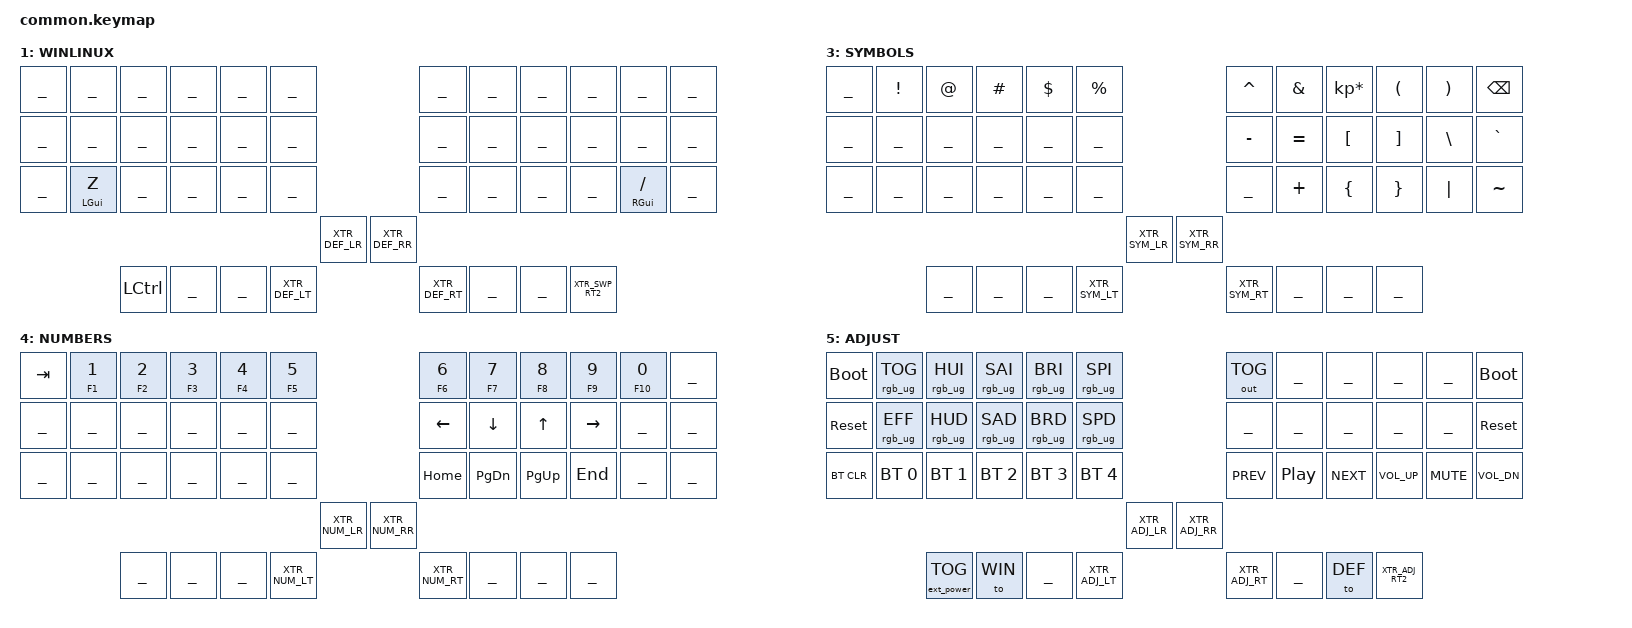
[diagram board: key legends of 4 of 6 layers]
#include <behaviors.dtsi>
#include <dt-bindings/zmk/keys.h>
#include <dt-bindings/zmk/bt.h>
#include <dt-bindings/zmk/rgb.h>
#include <dt-bindings/zmk/ext_power.h>
#include <dt-bindings/zmk/outputs.h>

#include "helpers.h"
#include "extra_keys_defaults.h"

// Left bottom row pinky 2nd column
#ifndef LB5
#define LB5 24
#endif

// Right bottom row pinky 2nd column
#ifndef RB5
#define RB5 35
#endif


#define DEF 0
#define WIN 1
#define SWP 2
#define SYM 3
#define NUM 4
#define ADJ 5


#define QUICK_TAP_MS 175

#define DEFAULT_LAYOUT \
      /* ╭─────────────┬─────────────┬─────────────┬─────────────┬─────────────┬─────────────╮                                      ╭─────────────┬─────────────┬─────────────┬─────────────┬─────────────┬────────────╮   */ \
          &ht GRAVE TAB,   &ht N1 Q,    &ht N2 W,     &ht N3 E,     &ht N4 R,     &ht N5 T,                                             &ht N6 Y,    &ht N7 U,     &ht N8 I,     &ht N9 O,     &ht N0 P,    &kp PIPE,         \
      /* ├─────────────┼─────────────┼─────────────┼─────────────┼─────────────┼─────────────┤                                      ├─────────────┼─────────────┼─────────────┼─────────────┼─────────────┼────────────┤   */ \
           &kp ESC,         &kp A,        &kp S,        &kp D,        &kp F,       &kp G,                                                &kp H,        &kp J,        &kp K,        &kp L,       &kp SEMI,    &kp SQT,         \
      /* ├─────────────┼─────────────┼─────────────┼─────────────┼─────────────┼─────────────┤  ╭─────────────╮     ╭─────────────╮ ├─────────────┼─────────────┼─────────────┼─────────────┼─────────────┼────────────┤   */ \
           &sk LSHFT,  &mt_sk LCTRL Z, &mt_sk LALT X,   &kp C,        &kp V,       &kp B,                                                &kp N,        &kp M,       &kp COMMA, &mt_sk RALT DOT, &mt_sk RCTRL FSLH, &sk RSHFT, \
                                                                                                  XTR_DEF_LR,          XTR_DEF_RR,                                                                                            \
      /* ╰─────────────┴─────────────┼─────────────┼─────────────┼─────────────┼─────────────┤  ╰─────────────╯     ╰─────────────╯ ├─────────────┼─────────────┼─────────────┼─────────────┼─────────────┴────────────╯   */ \
                                          &lswp,     &kp SPACE,  &lt_qk SYM BKSP, XTR_DEF_LT,                                          XTR_DEF_RT,  &lt_qk NUM DEL,  &kp RET,    &tog SWP  
      /*                             ╰─────────────┴─────────────┴─────────────┴─────────────╯                                      ╰─────────────┴─────────────┴─────────────┴─────────────╯                              */


&sk {
  release-after-ms = <600>;
  quick-release;
};

/ {
  conditional_layers {
    compatible = "zmk,conditional-layers";
    tri_layer {
      if-layers = <SYM NUM>;
      then-layer = <ADJ>;
    };
  };

  combos {
    compatible = "zmk,combos";
    caps {
      timeout-ms = <50>;
      key-positions = <LB5 RB5>;
      bindings = <&caps_word>;
    };
  };

  behaviors {
    lt_qk: layer_toggle_quick {
      compatible = "zmk,behavior-hold-tap";
      label = "LAYER_TOGGLE_QUICK";
      #binding-cells = <2>;
      flavor = "tap-preferred";
      tapping-term-ms = <150>;
      quick-tap-ms = <QUICK_TAP_MS>;
      bindings = <&mo>, <&kp>;
    };
    mt_sk: mod_tap_sticky {
      compatible = "zmk,behavior-hold-tap";
      label = "MOD_TAP_STICKY";
      #binding-cells = <2>;
      flavor = "tap-preferred";
      tapping-term-ms = <150>;
      quick-tap-ms = <200>;
      bindings = <&sk>, <&kp>;
    };
    ht: hold_tap {
      compatible = "zmk,behavior-hold-tap";
      label = "HOLD_TAP";
      #binding-cells = <2>;
      tapping_term_ms = <200>;
      quick_tap_ms = <200>;
      flavor = "tap-preferred";
      bindings = <&kp>, <&kp>;
    };
    lswp: lswp { \
        label = "SWAP"; \
        compatible = "zmk,behavior-tap-dance"; \
        #binding-cells = <0>; \
        tapping-term-ms = <200>; \
        bindings = <&sk LGUI>, <&tog SWP>; \
    }; \
  };

  keymap {
    compatible = "zmk,keymap";
    default_layer {
      label = "DEFAULT";
      bindings = <LAYOUT_wrapper(DEFAULT_LAYOUT)>;
    };
    
    winlinux_layer {
      label = "WINLINUX";
      bindings = <
      // ╭─────────────┬─────────────┬─────────────┬─────────────┬─────────────┬─────────────╮                                      ╭─────────────┬─────────────┬─────────────┬─────────────┬─────────────┬────────────╮
              ___          ___            ___            ___           ___          ___                                                  ___          ___            ___            ___           ___          ___       
      // ├─────────────┼─────────────┼─────────────┼─────────────┼─────────────┼─────────────┤                                      ├─────────────┼─────────────┼────────────┼─────────────┼─────────────┼────────────┤
              ___          ___            ___            ___           ___          ___                                                  ___          ___            ___            ___           ___          ___       
      // ├─────────────┼─────────────┼─────────────┼─────────────┼─────────────┼─────────────┤  ╭─────────────╮     ╭─────────────╮ ├─────────────┼─────────────┼─────────────┼─────────────┼─────────────┼────────────┤
              ___      &mt_sk LGUI Z      ___            ___           ___          ___                                                  ___           ___           ___            ___    &mt_sk RGUI FSLH    ___ 
                                                                                                  XTR_DEF_LR          XTR_DEF_RR                                                                                   
      // ╰─────────────┴─────────────┼─────────────┼─────────────┼─────────────┼─────────────┤  ╰─────────────╯     ╰─────────────╯ ├─────────────┼─────────────┼─────────────┼─────────────┼─────────────┴────────────╯
                                       &kp LCTRL         ___           ___        XTR_DEF_LT                                           XTR_DEF_RT      ___           ___        XTR_SWP_RT2        
      //                             ╰─────────────┴─────────────┴─────────────┴─────────────╯                                      ╰─────────────┴─────────────┴─────────────┴─────────────╯
      >;
    };
    swap_layer {
      label = "SWAP";
      bindings = <SWAP_LAYOUT_wrapper(DEFAULT_LAYOUT)>;
    };
    sym_layer {
      label = "SYMBOLS";
      bindings = <
      // ╭─────────────┬─────────────┬─────────────┬─────────────┬─────────────┬─────────────╮                                      ╭─────────────┬─────────────┬─────────────┬─────────────┬─────────────┬────────────╮
              ___          &kp EXCL      &kp AT        &kp HASH      &kp DLLR    &kp PRCNT                                             &kp CARET      &kp AMPS   &kp KP_MULTIPLY &kp LPAR       &kp RPAR     &kp BSPC
      // ├─────────────┼─────────────┼─────────────┼─────────────┼─────────────┼─────────────┤                                      ├─────────────┼─────────────┼─────────────┼─────────────┼─────────────┼────────────┤
              ___          ___            ___            ___           ___          ___                                                &kp MINUS      &kp EQUAL     &kp LBKT     &kp RBKT       &kp BSLH     &kp GRAVE
      // ├─────────────┼─────────────┼─────────────┼─────────────┼─────────────┼─────────────┤  ╭─────────────╮     ╭─────────────╮ ├─────────────┼─────────────┼─────────────┼─────────────┼─────────────┼────────────┤
              ___          ___            ___            ___           ___          ___                                                &kp UNDER      &kp PLUS      &kp LBRC     &kp RBRC       &kp PIPE     &kp TILDE
                                                                                                  XTR_SYM_LR          XTR_SYM_RR                                                                                      
      // ╰─────────────┴─────────────┼─────────────┼─────────────┼─────────────┼─────────────┤  ╰─────────────╯     ╰─────────────╯ ├─────────────┼─────────────┼─────────────┼─────────────┼─────────────┴────────────╯
                                           ___           ___           ___        XTR_SYM_LT                                           XTR_SYM_RT       ___            ___           ___         
      //                             ╰─────────────┴─────────────┴─────────────┴─────────────╯                                      ╰─────────────┴─────────────┴─────────────┴─────────────╯
      >;
    };
    num_layer {
      label = "NUMBERS";
      bindings = <
      // ╭─────────────┬─────────────┬─────────────┬─────────────┬─────────────┬─────────────╮                                      ╭─────────────┬─────────────┬─────────────┬─────────────┬─────────────┬────────────╮
            &kp TAB        &ht F1 N1     &ht F2 N2     &ht F3 N3    &ht F4 N4     &ht F5 N5                                           &ht F6 N6       &ht F7 N7   &ht F8 N8       &ht F9 N9    &ht F10 N0       ___
      // ├─────────────┼─────────────┼─────────────┼─────────────┼─────────────┼─────────────┤                                      ├─────────────┼─────────────┼─────────────┼─────────────┼─────────────┼────────────┤
               ___          ___            ___            ___           ___          ___                                               &kp LEFT       &kp DOWN    &kp UP          &kp RIGHT       ___           ___
      // ├─────────────┼─────────────┼─────────────┼─────────────┼─────────────┼─────────────┤  ╭─────────────╮     ╭─────────────╮ ├─────────────┼─────────────┼─────────────┼─────────────┼─────────────┼────────────┤
               ___          ___            ___            ___           ___          ___                                               &kp HOME      &kp PG_DN    &kp PG_UP       &kp END         ___           ___
                                                                                                   XTR_NUM_LR          XTR_NUM_RR                                                                                       
      // ╰─────────────┴─────────────┼─────────────┼─────────────┼─────────────┼─────────────┤  ╰─────────────╯     ╰─────────────╯ ├─────────────┼─────────────┼─────────────┼─────────────┼─────────────┴────────────╯
                                           ___            ___           ___        XTR_NUM_LT                                          XTR_NUM_RT       ___            ___           ___         
      //                             ╰─────────────┴─────────────┴─────────────┴─────────────╯                                      ╰─────────────┴─────────────┴─────────────┴─────────────╯
      >;
    };
    adj_layer {
      label = "ADJUST";
      bindings = <
      // ╭─────────────┬─────────────┬─────────────┬─────────────┬─────────────┬─────────────╮                                      ╭─────────────┬─────────────┬─────────────┬─────────────┬─────────────┬────────────╮
           &bootloader &rgb_ug RGB_TOG &rgb_ug RGB_HUI &rgb_ug RGB_SAI &rgb_ug RGB_BRI &rgb_ug RGB_SPI                               &out OUT_TOG       ___           ___           ___          ___        &bootloader
      // ├─────────────┼─────────────┼─────────────┼─────────────┼─────────────┼─────────────┤                                      ├─────────────┼─────────────┼─────────────┼─────────────┼─────────────┼────────────┤
           &sys_reset  &rgb_ug RGB_EFF &rgb_ug RGB_HUD &rgb_ug RGB_SAD &rgb_ug RGB_BRD &rgb_ug RGB_SPD                                     ___          ___           ___           ___          ___         &sys_reset
      // ├─────────────┼─────────────┼─────────────┼─────────────┼─────────────┼─────────────┤  ╭─────────────╮     ╭─────────────╮ ├─────────────┼─────────────┼─────────────┼─────────────┼─────────────┼────────────┤
           &bt BT_CLR  &bt BT_SEL 0    &bt BT_SEL 1 &bt BT_SEL 2  &bt BT_SEL 3  &bt BT_SEL 4                                         &kp C_PREV      &kp C_PP     &kp C_NEXT    &kp C_VOL_UP    &kp C_MUTE  &kp C_VOL_DN  
                                                                                                  XTR_ADJ_LR          XTR_ADJ_RR                                                                                 
      // ╰─────────────┴─────────────┼─────────────┼─────────────┼─────────────┼─────────────┤  ╰─────────────╯     ╰─────────────╯ ├─────────────┼─────────────┼─────────────┼─────────────┼─────────────┴────────────╯
                                   &ext_power EP_TOG   &to WIN         ___        XTR_ADJ_LT                                          XTR_ADJ_RT       ___          &to DEF     XTR_ADJ_RT2       
      //                             ╰─────────────┴─────────────┴─────────────┴─────────────╯                                      ╰─────────────┴─────────────┴─────────────┴─────────────╯
      >;
    };
  };
};
